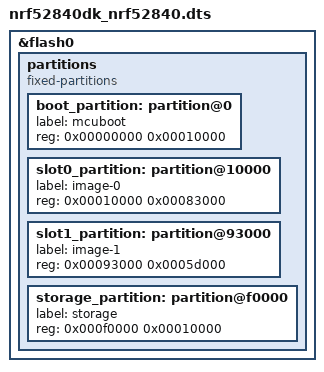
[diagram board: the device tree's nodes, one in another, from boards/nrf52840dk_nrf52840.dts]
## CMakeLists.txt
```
#
# Copyright (c) 2024 Nordic Semiconductor
#
# SPDX-License-Identifier: LicenseRef-Nordic-5-Clause
#

cmake_minimum_required(VERSION 3.20.0)

find_package(Zephyr REQUIRED HINTS $ENV{ZEPHYR_BASE})
project(mcuboot_update)

# This project uses orginal sdk-zephyr C source code
target_sources(app PRIVATE src/hook.c ${ZEPHYR_BASE}/samples/subsys/mgmt/mcumgr/smp_svr/src/main.c)
target_sources_ifdef(CONFIG_MCUMGR_TRANSPORT_BT app PRIVATE ${ZEPHYR_BASE}/samples/subsys/mgmt/mcumgr/smp_svr/src/bluetooth.c)
zephyr_link_libraries(MCUBOOT_BOOTUTIL)
```

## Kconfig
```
#
# Copyright (c) 2024 Nordic Semiconductor
#
# SPDX-License-Identifier: LicenseRef-Nordic-5-Clause
#

config OUTPUT_BOOT_MESSAGE
	bool "Output message on boot"
	help
	  Will output a dummy message on boot, this is to allow for generating a different image
	  that can be used to test the compressed firmware update.

source "Kconfig.zephyr"
```

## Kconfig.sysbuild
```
#
# Copyright (c) 2025 Nordic Semiconductor
#
# SPDX-License-Identifier: LicenseRef-Nordic-5-Clause
#

config PARTITION_MANAGER
	default n if SOC_SERIES_NRF52 || SOC_NRF54L15 || SOC_NRF54LM20A || SOC_NRF54LV10A

source "share/sysbuild/Kconfig"
```

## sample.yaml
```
common:
  sysbuild: true
  tags:
    - sysbuild
    - ci_samples_nrf_compress
  harness: console
  harness_config:
    type: multi_line
    ordered: true
    regex:
      - "Starting bootloader"
      - "Jumping to the first image slot"
      - "smp_bt_sample: Advertising successfully started"
  timeout: 15
tests:
  nrf_compress.mcuboot_update:
    platform_allow:
      - nrf52840dk/nrf52840
      - nrf5340dk/nrf5340/cpuapp
      - nrf54h20dk/nrf54h20/cpuapp
      - nrf54l15dk/nrf54l15/cpuapp
      - nrf54lm20dk/nrf54lm20a/cpuapp
      - nrf54lv10dk/nrf54lv10a/cpuapp
    integration_platforms:
      - nrf52840dk/nrf52840
      - nrf5340dk/nrf5340/cpuapp
      - nrf54l15dk/nrf54l15/cpuapp
      - nrf54lm20dk/nrf54lm20a/cpuapp
      - nrf54lv10dk/nrf54lv10a/cpuapp
```

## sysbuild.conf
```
#
# Copyright (c) 2024 Nordic Semiconductor
#
# SPDX-License-Identifier: LicenseRef-Nordic-5-Clause
#

SB_CONFIG_BOOTLOADER_MCUBOOT=y
SB_CONFIG_BOOT_SIGNATURE_TYPE_ECDSA_P256=y
SB_CONFIG_MCUBOOT_MODE_OVERWRITE_ONLY=y
SB_CONFIG_MCUBOOT_UPDATEABLE_IMAGES=1
SB_CONFIG_MCUBOOT_COMPRESSED_IMAGE_SUPPORT=y
SB_CONFIG_NETCORE_HCI_IPC=y
```

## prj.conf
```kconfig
# Enable MCUmgr and dependencies.
CONFIG_NET_BUF=y
CONFIG_ZCBOR=y
CONFIG_CRC=y
CONFIG_MCUMGR=y
CONFIG_STREAM_FLASH=y
CONFIG_FLASH_MAP=y

# Some command handlers require a large stack.
CONFIG_SYSTEM_WORKQUEUE_STACK_SIZE=2304
CONFIG_MAIN_STACK_SIZE=2048

# Ensure an MCUboot-compatible binary is generated.
CONFIG_BOOTLOADER_MCUBOOT=y

# Enable flash operations.
CONFIG_FLASH=y

# Required by the `taskstat` command.
CONFIG_THREAD_MONITOR=y

# Support for taskstat command
CONFIG_MCUMGR_GRP_OS_TASKSTAT=y

# Enable statistics and statistic names.
CONFIG_STATS=y
CONFIG_STATS_NAMES=y

# Enable most core commands.
CONFIG_FLASH=y
CONFIG_IMG_MANAGER=y
CONFIG_MCUMGR_GRP_IMG=y
CONFIG_MCUMGR_GRP_OS=y
CONFIG_MCUMGR_GRP_STAT=y

# Enable logging
CONFIG_LOG=y
CONFIG_MCUBOOT_UTIL_LOG_LEVEL_WRN=y

# Disable debug logging
CONFIG_LOG_MAX_LEVEL=3

CONFIG_BT=y
CONFIG_BT_PERIPHERAL=y

# Allow for large Bluetooth data packets.
CONFIG_BT_L2CAP_TX_MTU=498
CONFIG_BT_BUF_ACL_RX_SIZE=502
CONFIG_BT_BUF_ACL_TX_SIZE=502
CONFIG_BT_CTLR_DATA_LENGTH_MAX=251

# Enable the Bluetooth mcumgr transport (unauthenticated).
CONFIG_MCUMGR_TRANSPORT_BT=y
CONFIG_MCUMGR_TRANSPORT_BT_PERM_RW=y
CONFIG_MCUMGR_TRANSPORT_BT_CONN_PARAM_CONTROL=y

# Enable the Shell mcumgr transport.
CONFIG_BASE64=y
CONFIG_SHELL=y
CONFIG_SHELL_BACKEND_SERIAL=y
CONFIG_MCUMGR_TRANSPORT_SHELL=y
CONFIG_MCUMGR_TRANSPORT_SHELL_RX_BUF_COUNT=8

# Enable the mcumgr Packet Reassembly feature over Bluetooth and its configuration dependencies.
# MCUmgr buffer size is optimized to fit one SMP packet divided into five Bluetooth Write Commands,
# transmitted with the maximum possible MTU value: 498 bytes.
CONFIG_MCUMGR_TRANSPORT_BT_REASSEMBLY=y
CONFIG_MCUMGR_TRANSPORT_NETBUF_SIZE=2475
CONFIG_MCUMGR_GRP_OS_MCUMGR_PARAMS=y
CONFIG_MCUMGR_TRANSPORT_WORKQUEUE_STACK_SIZE=4608

# Disable Bluetooth ping support
CONFIG_BT_CTLR_LE_PING=n

# Disable shell commands that are not needed
CONFIG_CLOCK_CONTROL_NRF_SHELL=n
CONFIG_DEVICE_SHELL=n
CONFIG_DEVMEM_SHELL=n
CONFIG_FLASH_SHELL=n

CONFIG_MCUMGR_MGMT_NOTIFICATION_HOOKS=y
CONFIG_MCUMGR_GRP_IMG_STATUS_HOOKS=y
CONFIG_MCUMGR_GRP_IMG_IMAGE_SLOT_STATE_HOOK=y
CONFIG_MCUMGR_GRP_IMG_IMAGE_SLOT_STATE_STATES=20
```

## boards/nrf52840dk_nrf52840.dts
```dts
/*
 * Copyright (c) 2025 Nordic Semiconductor ASA
 *
 * SPDX-License-Identifier: LicenseRef-Nordic-5-Clause
 */

/delete-node/ &boot_partition;
/delete-node/ &slot0_partition;
/delete-node/ &slot1_partition;
/delete-node/ &storage_partition;

&flash0 {
	partitions {
		compatible = "fixed-partitions";
		#address-cells = <1>;
		#size-cells = <1>;

		boot_partition: partition@0 {
			label = "mcuboot";
			reg = <0x00000000 0x00010000>;
		};

		slot0_partition: partition@10000 {
			label = "image-0";
			reg = <0x00010000 0x00083000>;
		};

		slot1_partition: partition@93000 {
			label = "image-1";
			reg = <0x00093000 0x0005d000>;
		};

		storage_partition: partition@f0000 {
			label = "storage";
			reg = <0x000f0000 0x00010000>;
		};
	};
};
```

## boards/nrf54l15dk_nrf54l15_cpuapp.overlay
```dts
/*
 * Copyright (c) 2025 Nordic Semiconductor ASA
 *
 * SPDX-License-Identifier: LicenseRef-Nordic-5-Clause
 */

/delete-node/ &boot_partition;
/delete-node/ &slot0_partition;
/delete-node/ &slot1_partition;
/delete-node/ &storage_partition;

&cpuapp_rram {
	partitions {
		compatible = "fixed-partitions";
		#address-cells = <1>;
		#size-cells = <1>;

		boot_partition: partition@0 {
			label = "mcuboot";
			reg = <0x00000000 0x0000b000>;
		};

		slot0_partition: partition@b000 {
			label = "image-0";
			reg = <0x0000b000 0x000c4000>;
		};

		slot1_partition: partition@cf000 {
			label = "image-1";
			reg = <0x000cf000 0x00086000>;
		};

		storage_partition: partition@155000 {
			label = "storage";
			reg = <0x00155000 0x00010000>;
		};
	};
};
```

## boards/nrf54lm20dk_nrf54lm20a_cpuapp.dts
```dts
/*
 * Copyright (c) 2025 Nordic Semiconductor ASA
 *
 * SPDX-License-Identifier: LicenseRef-Nordic-5-Clause
 */

/delete-node/ &boot_partition;
/delete-node/ &slot0_partition;
/delete-node/ &slot1_partition;
/delete-node/ &storage_partition;

&cpuapp_rram {
	partitions {
		compatible = "fixed-partitions";
		#address-cells = <1>;
		#size-cells = <1>;

		boot_partition: partition@0 {
			label = "mcuboot";
			reg = <0x00000000 0x00010000>;
		};

		slot0_partition: partition@10000 {
			label = "image-0";
			reg = <0x00010000 0x00133000>;
		};

		slot1_partition: partition@143000 {
			label = "image-1";
			reg = <0x00143000 0x000aa000>;
		};

		storage_partition: partition@1ed000 {
			label = "storage";
			reg = <0x001ed000 0x00010000>;
		};
	};
};
```

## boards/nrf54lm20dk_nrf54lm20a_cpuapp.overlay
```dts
/*
 * Copyright (c) 2025 Nordic Semiconductor ASA
 *
 * SPDX-License-Identifier: LicenseRef-Nordic-5-Clause
 */

/delete-node/ &boot_partition;
/delete-node/ &slot0_partition;
/delete-node/ &slot1_partition;
/delete-node/ &storage_partition;

&cpuapp_rram {
	partitions {
		compatible = "fixed-partitions";
		#address-cells = <1>;
		#size-cells = <1>;

		boot_partition: partition@0 {
			label = "mcuboot";
			reg = <0x00000000 0x00010000>;
		};

		slot0_partition: partition@10000 {
			label = "image-0";
			reg = <0x00010000 0x00123000>;
		};

		slot1_partition: partition@133000 {
			label = "image-1";
			reg = <0x00133000 0x000a2000>;
		};

		storage_partition: partition@1d5000 {
			label = "storage";
			reg = <0x001d5000 0x00010000>;
		};
	};
};
```

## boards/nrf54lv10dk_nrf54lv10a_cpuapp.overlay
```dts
/*
 * Copyright (c) 2026 Nordic Semiconductor ASA
 *
 * SPDX-License-Identifier: LicenseRef-Nordic-5-Clause
 */

/delete-node/ &boot_partition;
/delete-node/ &slot0_partition;
/delete-node/ &slot1_partition;

&cpuapp_rram {
	partitions {
		compatible = "fixed-partitions";
		#address-cells = <1>;
		#size-cells = <1>;

		boot_partition: partition@0 {
			label = "mcuboot";
			reg = <0x00000000 0x0000b000>;
		};

		slot0_partition: partition@b000 {
			label = "image-0";
			reg = <0x0000b000 0x00035000>;
		};

		slot1_partition: partition@40000 {
			label = "image-1";
			reg = <0x00040000 0x00035000>;
		};
	};
};
```

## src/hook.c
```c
/*
 * Copyright (c) 2024 Nordic Semiconductor ASA
 *
 * SPDX-License-Identifier: LicenseRef-Nordic-5-Clause
 */

#include <zephyr/kernel.h>
#include <zephyr/init.h>
#include <zephyr/storage/flash_map.h>
#include <zephyr/mgmt/mcumgr/mgmt/mgmt.h>
#include <zephyr/mgmt/mcumgr/mgmt/callbacks.h>
#include <zephyr/mgmt/mcumgr/grp/img_mgmt/img_mgmt.h>
#include <zephyr/logging/log.h>
#include <zcbor_common.h>
#include <zcbor_encode.h>
#include <bootutil/image.h>

LOG_MODULE_REGISTER(mcuboot_update_sample, LOG_LEVEL_DBG);

#ifndef CONFIG_MCUMGR_GRP_IMG_FRUGAL_LIST
#define ZCBOR_ENCODE_FLAG(zse, label, value) \
	(zcbor_tstr_put_lit(zse, label) && zcbor_bool_put(zse, value))
#else
/* In "frugal" lists flags are added to response only when they evaluate to true */
/* Note that value is evaluated twice! */
#define ZCBOR_ENCODE_FLAG(zse, label, value) (!(value) || \
	 (zcbor_tstr_put_lit(zse, label) && zcbor_bool_put(zse, (value))))
#endif

static struct mgmt_callback image_slot_callback;
static struct k_work slot_output_work;

static void slot_output_handler(struct k_work *work)
{
	uint32_t slot;
	uint32_t slot_flags;
	int rc;

	for (size_t img = 0; img < CONFIG_UPDATEABLE_IMAGE_NUMBER; img++) {
		slot = (img * 2) + 1;

		rc = img_mgmt_read_info(slot, NULL, NULL, &slot_flags);
		if (rc) {
			continue;
		}

		slot_flags &= IMAGE_F_COMPRESSED_LZMA2 | IMAGE_F_COMPRESSED_ARM_THUMB_FLT;
		if (slot_flags == (IMAGE_F_COMPRESSED_LZMA2 | IMAGE_F_COMPRESSED_ARM_THUMB_FLT)) {
			LOG_INF("Secondary slot image %d is LZMA2 compressed with ARM thumb filter "
				"applied",
				img);
		} else if (slot_flags & IMAGE_F_COMPRESSED_LZMA2) {
			LOG_INF("Secondary slot image %d is LZMA2 compressed", img);
		} else {
			LOG_INF("Secondary slot image %d is uncompressed", img);
		}
	}
}

static enum mgmt_cb_return image_slot_state_cb(uint32_t event, enum mgmt_cb_return prev_status,
					       int32_t *rc, uint16_t *group, bool *abort_more,
					       void *data, size_t data_size)
{
	if (event == MGMT_EVT_OP_IMG_MGMT_IMAGE_SLOT_STATE) {
		/* Append a field indicating if the image in the slot is compressed */
		struct img_mgmt_state_slot_encode *slot_data =
						(struct img_mgmt_state_slot_encode *)data;

		*slot_data->ok = ZCBOR_ENCODE_FLAG(slot_data->zse, "compressed",
						  (slot_data->flags & IMAGE_F_COMPRESSED_LZMA2));
	} else if (event == MGMT_EVT_OP_IMG_MGMT_DFU_PENDING) {
		(void)k_work_submit(&slot_output_work);
	}

	return MGMT_CB_OK;
}

static int setup_slot_hook(void)
{
	/* Setup hook for when img mgmt image slot state is used and DFU pending callback */
	image_slot_callback.callback = image_slot_state_cb;
	image_slot_callback.event_id = MGMT_EVT_OP_IMG_MGMT_IMAGE_SLOT_STATE |
				       MGMT_EVT_OP_IMG_MGMT_DFU_PENDING;
	mgmt_callback_register(&image_slot_callback);
	k_work_init(&slot_output_work, slot_output_handler);

#if defined(CONFIG_OUTPUT_BOOT_MESSAGE)
	LOG_INF("Dummy message indicating new firmware is running...");
#endif

	return 0;
}

SYS_INIT(setup_slot_hook, APPLICATION, 0);
```
